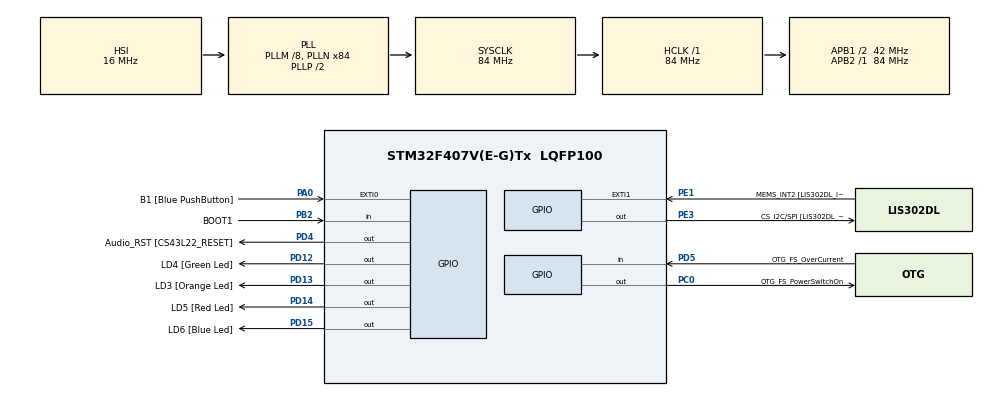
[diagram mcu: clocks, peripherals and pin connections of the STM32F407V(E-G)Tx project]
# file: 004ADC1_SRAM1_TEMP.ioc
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PA11.GPIO_Speed=GPIO_SPEED_FREQ_LOW
PD12.GPIO_Label=LD4 [Green Led]
PH0-OSC_IN.Signal=RCC_OSC_IN
ADC1.Rank-14\#ChannelRegularConversion=15
PC10.GPIO_PuPd=GPIO_NOPULL
PB10.GPIO_PuPd=GPIO_NOPULL
VP_ADC1_TempSens_Input.Mode=IN-TempSens
PA10.GPIO_PuPd=GPIO_NOPULL
ADC1.SamplingTime-6\#ChannelRegularConversion=ADC_SAMPLETIME_3CYCLES
PC12.Signal=I2S3_SD
PA14.GPIO_Label=SWCLK
PA6.GPIO_Label=SPI1_MISO [LIS302DL_SDO]
PB6.GPIO_Label=Audio_SCL [CS43L22_SCL]
ADC1.SamplingTime-12\#ChannelRegularConversion=ADC_SAMPLETIME_3CYCLES
PC15-OSC32_OUT.GPIO_Label=PC15-OSC32_OUT
ADC1.Channel-8\#ChannelRegularConversion=ADC_CHANNEL_TEMPSENSOR
PC3.GPIO_Speed=GPIO_SPEED_FREQ_LOW
RCC.SYSCLKSource=RCC_SYSCLKSOURCE_PLLCLK
PA6.GPIO_Mode=GPIO_MODE_AF_PP
PD14.GPIO_Speed=GPIO_SPEED_FREQ_LOW
ADC1.Channel-5\#ChannelRegularConversion=ADC_CHANNEL_TEMPSENSOR
ADC1.Rank-11\#ChannelRegularConversion=12
PD4.Signal=GPIO_Output
RCC.APB2TimFreq_Value=84000000
Dma.ADC1.0.Direction=DMA_PERIPH_TO_MEMORY
PB6.Signal=I2C1_SCL
ADC1.Channel-2\#ChannelRegularConversion=ADC_CHANNEL_TEMPSENSOR
PC7.Signal=I2S3_MCK
PC3.Signal=I2S2_SD
PE1.Signal=GPXTI1
Dma.ADC1.0.MemDataAlignment=DMA_MDATAALIGN_HALFWORD
PB2.Signal=GPIO_Input
PA5.GPIO_PuPd=GPIO_NOPULL
Dma.ADC1.0.PeriphInc=DMA_PINC_DISABLE
PD5.GPIO_Mode=GPIO_MODE_INPUT
PD14.GPIO_PuPd=GPIO_NOPULL
ADC1.Channel-15\#ChannelRegularConversion=ADC_CHANNEL_TEMPSENSOR
PB2.GPIO_PuPd=GPIO_NOPULL
ADC1.SamplingTime-0\#ChannelRegularConversion=ADC_SAMPLETIME_3CYCLES
PB9.Signal=I2C1_SDA
Mcu.Package=LQFP100
PD12.Signal=GPIO_Output
PA10.Signal=USB_OTG_FS_ID
PB9.GPIO_PuPd=GPIO_NOPULL
ADC1.SamplingTime-15\#ChannelRegularConversion=ADC_SAMPLETIME_3CYCLES
RCC.APB1TimFreq_Value=84000000
Dma.ADC1.0.FIFOMode=DMA_FIFOMODE_DISABLE
PC12.GPIO_PuPd=GPIO_NOPULL
PA6.GPIO_Speed=GPIO_SPEED_FREQ_LOW
PA12.GPIO_PuPd=GPIO_NOPULL
PA4.GPIO_Label=I2S3_WS [CS43L22_LRCK]
PD15.Signal=GPIO_Output
PC0.PinState=GPIO_PIN_SET
ADC1.Rank-4\#ChannelRegularConversion=5
ADC1.Channel-10\#ChannelRegularConversion=ADC_CHANNEL_TEMPSENSOR
Dma.ADC1.0.Instance=DMA2_Stream0
ADC1.Rank-0\#ChannelRegularConversion=1
PA9.GPIO_Label=VBUS_FS
PB6.GPIO_PuPd=GPIO_NOPULL
PA11.GPIO_Label=OTG_FS_DM
PE1.GPIO_PuPd=GPIO_NOPULL
PC0.Signal=GPIO_Output
RCC.APB1CLKDivider=RCC_HCLK_DIV2
PC14-OSC32_IN.Signal=RCC_OSC32_IN
PA0-WKUP.GPIO_Label=B1 [Blue PushButton]
PA0-WKUP.Signal=GPXTI0
ADC1.Channel-7\#ChannelRegularConversion=ADC_CHANNEL_TEMPSENSOR
PC10.GPIO_Mode=GPIO_MODE_AF_PP
PB10.GPIO_Mode=GPIO_MODE_AF_PP
Dma.ADC1.0.Priority=DMA_PRIORITY_LOW
PA9.Signal=USB_OTG_FS_VBUS
PC7.GPIO_PuPd=GPIO_NOPULL
PB10.Signal=I2S2_CK
PA5.Signal=SPI1_SCK
ADC1.Rank-12\#ChannelRegularConversion=13
PE1.GPIO_Label=MEMS_INT2 [LIS302DL_INT2]
PA7.GPIO_Speed=GPIO_SPEED_FREQ_LOW
ADC1.SamplingTime-14\#ChannelRegularConversion=ADC_SAMPLETIME_3CYCLES
PB2.GPIO_Mode=GPIO_MODE_INPUT
PD4.GPIO_Speed=GPIO_SPEED_FREQ_LOW
PE3.GPIO_PuPd=GPIO_NOPULL
PH1-OSC_OUT.GPIO_Label=PH1-OSC_OUT
ADC1.DMAContinuousRequests=ENABLE
ADC1.SamplingTime-10\#ChannelRegularConversion=ADC_SAMPLETIME_3CYCLES
ADC1.Rank-9\#ChannelRegularConversion=10
PC7.GPIO_Label=I2S3_MCK [CS43L22_MCLK]
ADC1.SamplingTime-1\#ChannelRegularConversion=ADC_SAMPLETIME_3CYCLES
PA4.Signal=I2S3_WS
PC12.GPIO_Mode=GPIO_MODE_AF_PP
ADC1.master=1
PA5.GPIO_Label=SPI1_SCK [LIS302DL_SCL/SPC]
PE3.GPIO_Speed=GPIO_SPEED_FREQ_LOW
PC12.GPIO_Label=I2S3_SD [CS43L22_SDIN]
ADC1.Rank-1\#ChannelRegularConversion=2
PA11.Signal=USB_OTG_FS_DM
ProjectManager.HeapSize=0x200
ADC1.SamplingTime-5\#ChannelRegularConversion=ADC_SAMPLETIME_3CYCLES
NVIC.PriorityGroup=NVIC_PRIORITYGROUP_0
PE3.Signal=GPIO_Output
PC3.GPIO_Label=PDM_OUT [MP45DT02_DOUT]
ADC1.SamplingTime-9\#ChannelRegularConversion=ADC_SAMPLETIME_3CYCLES
PB6.GPIO_Speed=GPIO_SPEED_FREQ_LOW
ADC1.Rank-5\#ChannelRegularConversion=6
Mcu.Family=STM32F4
PC3.GPIO_Mode=GPIO_MODE_AF_PP
RCC.CortexFreq_Value=84000000
PB10.GPIO_Speed=GPIO_SPEED_FREQ_LOW
PB6.GPIO_Mode=GPIO_MODE_AF_OD
ADC1.ContinuousConvMode=ENABLE
PD15.GPIO_Speed=GPIO_SPEED_FREQ_LOW
PC10.Signal=I2S3_CK
PA7.GPIO_Mode=GPIO_MODE_AF_PP
PC0.GPIO_Label=OTG_FS_PowerSwitchOn
PC10.GPIO_Speed=GPIO_SPEED_FREQ_LOW
PA11.GPIO_PuPd=GPIO_NOPULL
ADC1.Channel-14\#ChannelRegularConversion=ADC_CHANNEL_TEMPSENSOR
ProjectManager.StackSize=0x400
PD13.Signal=GPIO_Output
PA12.Signal=USB_OTG_FS_DP
ADC1.Channel-3\#ChannelRegularConversion=ADC_CHANNEL_TEMPSENSOR
RCC.HCLKFreq_Value=84000000
NVIC.DMA2_Stream0_IRQn=true\:0\:0\:false\:false\:true\:false\:true
RCC.AHBFreq_Value=84000000
PH0-OSC_IN.GPIO_Label=PH0-OSC_IN
PA9.GPIO_Mode=GPIO_MODE_INPUT
ADC1.Channel-0\#ChannelRegularConversion=ADC_CHANNEL_TEMPSENSOR
RCC.HSE_VALUE=8000000
PA4.GPIO_PuPd=GPIO_NOPULL
PA4.GPIO_Speed=GPIO_SPEED_FREQ_LOW
ADC1.SamplingTime-4\#ChannelRegularConversion=ADC_SAMPLETIME_3CYCLES
ADC1.Channel-6\#ChannelRegularConversion=ADC_CHANNEL_TEMPSENSOR
PA6.GPIO_PuPd=GPIO_NOPULL
ADC1.Rank-2\#ChannelRegularConversion=3
PA10.GPIO_Label=OTG_FS_ID
PC7.GPIO_Mode=GPIO_MODE_AF_PP
ADC1.Rank-15\#ChannelRegularConversion=16
PD13.GPIO_Label=LD3 [Orange Led]
ADC1.SamplingTime-11\#ChannelRegularConversion=ADC_SAMPLETIME_3CYCLES
PA6.Signal=SPI1_MISO
PD5.GPIO_Label=OTG_FS_OverCurrent
ADC1.SamplingTime-13\#ChannelRegularConversion=ADC_SAMPLETIME_3CYCLES
PD15.GPIO_PuPd=GPIO_NOPULL
ADC1.Channel-11\#ChannelRegularConversion=ADC_CHANNEL_TEMPSENSOR
PA10.GPIO_Speed=GPIO_SPEED_FREQ_LOW
PB9.GPIO_Speed=GPIO_SPEED_FREQ_LOW
PC14-OSC32_IN.GPIO_Label=PC14-OSC32_IN
PC0.GPIO_PuPd=GPIO_NOPULL
ADC1.Rank-6\#ChannelRegularConversion=7
Dma.Request0=ADC1
ADC1.SamplingTime-8\#ChannelRegularConversion=ADC_SAMPLETIME_3CYCLES
PA12.GPIO_Speed=GPIO_SPEED_FREQ_LOW
PB3.GPIO_Label=SWO
PD12.GPIO_Speed=GPIO_SPEED_FREQ_LOW
PD15.GPIO_Label=LD6 [Blue Led]
PB9.GPIO_Label=Audio_SDA [CS43L22_SDA]
ADC1.Channel-4\#ChannelRegularConversion=ADC_CHANNEL_TEMPSENSOR
PC10.GPIO_Label=I2S3_SCK [CS43L22_SCLK]
ADC1.Rank-10\#ChannelRegularConversion=11
ADC1.Rank-8\#ChannelRegularConversion=9
PD5.Signal=GPIO_Input
ADC1.Channel-13\#ChannelRegularConversion=ADC_CHANNEL_TEMPSENSOR
PE1.GPIO_ModeDefaultEXTI=GPIO_MODE_EVT_RISING
PA9.GPIO_PuPd=GPIO_NOPULL
PA12.GPIO_Label=OTG_FS_DP
ADC1.SamplingTime-2\#ChannelRegularConversion=ADC_SAMPLETIME_3CYCLES
PA10.GPIO_Mode=GPIO_MODE_AF_PP
PA13.Signal=SYS_JTMS-SWDIO
ADC1.Rank-13\#ChannelRegularConversion=14
PD4.GPIO_PuPd=GPIO_NOPULL
Dma.ADC1.0.PeriphDataAlignment=DMA_PDATAALIGN_HALFWORD
PC0.GPIO_Speed=GPIO_SPEED_FREQ_LOW
ProjectManager.TargetToolchain=STM32CubeIDE
PB10.GPIO_Label=CLK_IN [MP45DT02_CLK]
Dma.ADC1.0.Mode=DMA_NORMAL
ADC1.Channel-1\#ChannelRegularConversion=ADC_CHANNEL_TEMPSENSOR
RCC.LSE_VALUE=32768
PC15-OSC32_OUT.Signal=RCC_OSC32_OUT
PA7.GPIO_PuPd=GPIO_NOPULL
board=STM32F407G-DISC1
PD13.GPIO_Speed=GPIO_SPEED_FREQ_LOW
PC7.GPIO_Speed=GPIO_SPEED_FREQ_LOW
RCC.VCOOutputFreq_Value=168000000
PB9.GPIO_Mode=GPIO_MODE_AF_OD
PA12.GPIO_Mode=GPIO_MODE_AF_PP
PA4.GPIO_Mode=GPIO_MODE_AF_PP
ADC1.Channel-12\#ChannelRegularConversion=ADC_CHANNEL_TEMPSENSOR
RCC.APB2Freq_Value=84000000
PD4.GPIO_Label=Audio_RST [CS43L22_RESET]
PH1-OSC_OUT.Signal=RCC_OSC_OUT
PD13.GPIO_PuPd=GPIO_NOPULL
PD5.GPIO_PuPd=GPIO_NOPULL
PD14.GPIO_Label=LD5 [Red Led]
ADC1.NbrOfConversion=16
Mcu.Name=STM32F407V(E-G)Tx
PA13.GPIO_Label=SWDIO
ADC1.Channel-9\#ChannelRegularConversion=ADC_CHANNEL_TEMPSENSOR
PD14.Signal=GPIO_Output
RCC.48MHZClocksFreq_Value=24000000
PB3.Signal=SYS_JTDO-SWO
NVIC.EXTI0_IRQn=true\:0\:0\:false\:false\:true\:true\:true
RCC.SYSCLKFreq_VALUE=84000000
PA7.GPIO_Label=SPI1_MOSI [LIS302DL_SDA/SDI/SDO]
ADC1.Rank-3\#ChannelRegularConversion=4
ADC1.SamplingTime-3\#ChannelRegularConversion=ADC_SAMPLETIME_3CYCLES
PA14.Signal=SYS_JTCK-SWCLK
Dma.ADC1.0.MemInc=DMA_MINC_ENABLE
PB2.GPIO_Label=BOOT1
RCC.HSI_VALUE=16000000
ADC1.Rank-7\#ChannelRegularConversion=8
PA5.GPIO_Speed=GPIO_SPEED_FREQ_LOW
RCC.PLLQ=7
ADC1.NbrOfConversionFlag=1
RCC.PLLM=8
RCC.PLLN=84
PE3.GPIO_Label=CS_I2C/SPI [LIS302DL_CS_I2C/SPI]
ADC1.SamplingTime-7\#ChannelRegularConversion=ADC_SAMPLETIME_3CYCLES
PA11.GPIO_Mode=GPIO_MODE_AF_PP
RCC.APB1Freq_Value=42000000
PA5.GPIO_Mode=GPIO_MODE_AF_PP
PC12.GPIO_Speed=GPIO_SPEED_FREQ_LOW
PC3.GPIO_PuPd=GPIO_NOPULL
PD12.GPIO_PuPd=GPIO_NOPULL
PA7.Signal=SPI1_MOSI

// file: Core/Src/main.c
/* USER CODE BEGIN Header */
/**
  ******************************************************************************
  * @file           : main.c
  * @brief          : Main program body
  ******************************************************************************
  * @attention
  *
  * <h2><center>&copy; Copyright (c) 2021 STMicroelectronics.
  * All rights reserved.</center></h2>
  *
  * This software component is licensed by ST under BSD 3-Clause license,
  * the "License"; You may not use this file except in compliance with the
  * License. You may obtain a copy of the License at:
  *                        opensource.org/licenses/BSD-3-Clause
  *
  ******************************************************************************
  */
/* USER CODE END Header */
#include "main.h"

/* USER CODE BEGIN Includes */
#include <stdint.h>
/* USER CODE END Includes */

ADC_HandleTypeDef hadc1;
DMA_HandleTypeDef hdma_adc1;

/* USER CODE BEGIN PV */

uint16_t temp_data[16];

/* USER CODE END PV */

void SystemClock_Config(void);
static void MX_GPIO_Init(void);
static void MX_DMA_Init(void);
static void MX_ADC1_Init(void);

int main(void)
{

  /* MCU Configuration--------------------------------------------------------*/

  /* Reset of all peripherals, Initializes the Flash interface and the Systick. */
  HAL_Init();

  /* Configure the system clock */
  SystemClock_Config();

  /* Initialize all configured peripherals */
  MX_GPIO_Init();
  MX_DMA_Init();
  MX_ADC1_Init();

  /* Infinite loop */
  while (1)
  {

  }
}

void SystemClock_Config(void)
{
  RCC_OscInitTypeDef RCC_OscInitStruct = {0};
  RCC_ClkInitTypeDef RCC_ClkInitStruct = {0};

  /** Configure the main internal regulator output voltage
  */
  __HAL_RCC_PWR_CLK_ENABLE();
  __HAL_PWR_VOLTAGESCALING_CONFIG(PWR_REGULATOR_VOLTAGE_SCALE1);
  /** Initializes the RCC Oscillators according to the specified parameters
  * in the RCC_OscInitTypeDef structure.
  */
  RCC_OscInitStruct.OscillatorType = RCC_OSCILLATORTYPE_HSI;
  RCC_OscInitStruct.HSIState = RCC_HSI_ON;
  RCC_OscInitStruct.HSICalibrationValue = RCC_HSICALIBRATION_DEFAULT;
  RCC_OscInitStruct.PLL.PLLState = RCC_PLL_ON;
  RCC_OscInitStruct.PLL.PLLSource = RCC_PLLSOURCE_HSI;
  RCC_OscInitStruct.PLL.PLLM = 8;
  RCC_OscInitStruct.PLL.PLLN = 84;
  RCC_OscInitStruct.PLL.PLLP = RCC_PLLP_DIV2;
  RCC_OscInitStruct.PLL.PLLQ = 7;
  if (HAL_RCC_OscConfig(&RCC_OscInitStruct) != HAL_OK)
  {
    Error_Handler();
  }
  /** Initializes the CPU, AHB and APB buses clocks
  */
  RCC_ClkInitStruct.ClockType = RCC_CLOCKTYPE_HCLK|RCC_CLOCKTYPE_SYSCLK
                              |RCC_CLOCKTYPE_PCLK1|RCC_CLOCKTYPE_PCLK2;
  RCC_ClkInitStruct.SYSCLKSource = RCC_SYSCLKSOURCE_PLLCLK;
  RCC_ClkInitStruct.AHBCLKDivider = RCC_SYSCLK_DIV1;
  RCC_ClkInitStruct.APB1CLKDivider = RCC_HCLK_DIV2;
  RCC_ClkInitStruct.APB2CLKDivider = RCC_HCLK_DIV1;

  if (HAL_RCC_ClockConfig(&RCC_ClkInitStruct, FLASH_LATENCY_2) != HAL_OK)
  {
    Error_Handler();
  }
}

static void MX_ADC1_Init(void)
{

  ADC_ChannelConfTypeDef sConfig = {0};

  /** Configure the global features of the ADC (Clock, Resolution, Data Alignment and number of conversion)
  */
  hadc1.Instance = ADC1;
  hadc1.Init.ClockPrescaler = ADC_CLOCK_SYNC_PCLK_DIV4;
  hadc1.Init.Resolution = ADC_RESOLUTION_12B;
  hadc1.Init.ScanConvMode = DISABLE;
  hadc1.Init.ContinuousConvMode = ENABLE;
  hadc1.Init.DiscontinuousConvMode = DISABLE;
  hadc1.Init.ExternalTrigConvEdge = ADC_EXTERNALTRIGCONVEDGE_NONE;
  hadc1.Init.ExternalTrigConv = ADC_SOFTWARE_START;
  hadc1.Init.DataAlign = ADC_DATAALIGN_RIGHT;
  hadc1.Init.NbrOfConversion = 16;
  hadc1.Init.DMAContinuousRequests = ENABLE;
  hadc1.Init.EOCSelection = ADC_EOC_SINGLE_CONV;
  if (HAL_ADC_Init(&hadc1) != HAL_OK)
  {
    Error_Handler();
  }
  /** Configure for the selected ADC regular channel its corresponding rank in the sequencer and its sample time.
  */
  sConfig.Channel = ADC_CHANNEL_TEMPSENSOR;
  sConfig.Rank = 1;
  sConfig.SamplingTime = ADC_SAMPLETIME_3CYCLES;
  if (HAL_ADC_ConfigChannel(&hadc1, &sConfig) != HAL_OK)
  {
    Error_Handler();
  }
  /** Configure for the selected ADC regular channel its corresponding rank in the sequencer and its sample time.
  */
  sConfig.Rank = 2;
  if (HAL_ADC_ConfigChannel(&hadc1, &sConfig) != HAL_OK)
  {
    Error_Handler();
  }
  /** Configure for the selected ADC regular channel its corresponding rank in the sequencer and its sample time.
  */
  sConfig.Rank = 3;
  if (HAL_ADC_ConfigChannel(&hadc1, &sConfig) != HAL_OK)
  {
    Error_Handler();
  }
  /** Configure for the selected ADC regular channel its corresponding rank in the sequencer and its sample time.
  */
  sConfig.Rank = 4;
  if (HAL_ADC_ConfigChannel(&hadc1, &sConfig) != HAL_OK)
  {
    Error_Handler();
  }
  /** Configure for the selected ADC regular channel its corresponding rank in the sequencer and its sample time.
  */
  sConfig.Rank = 5;
  if (HAL_ADC_ConfigChannel(&hadc1, &sConfig) != HAL_OK)
  {
    Error_Handler();
  }
  /** Configure for the selected ADC regular channel its corresponding rank in the sequencer and its sample time.
  */
  sConfig.Rank = 6;
  if (HAL_ADC_ConfigChannel(&hadc1, &sConfig) != HAL_OK)
  {
    Error_Handler();
  }
  /** Configure for the selected ADC regular channel its corresponding rank in the sequencer and its sample time.
  */
  sConfig.Rank = 7;
  if (HAL_ADC_ConfigChannel(&hadc1, &sConfig) != HAL_OK)
  {
    Error_Handler();
  }
  /** Configure for the selected ADC regular channel its corresponding rank in the sequencer and its sample time.
  */
  sConfig.Rank = 8;
  if (HAL_ADC_ConfigChannel(&hadc1, &sConfig) != HAL_OK)
  {
    Error_Handler();
  }
  /** Configure for the selected ADC regular channel its corresponding rank in the sequencer and its sample time.
  */
  sConfig.Rank = 9;
  if (HAL_ADC_ConfigChannel(&hadc1, &sConfig) != HAL_OK)
  {
    Error_Handler();
  }
  /** Configure for the selected ADC regular channel its corresponding rank in the sequencer and its sample time.
  */
  sConfig.Rank = 10;
  if (HAL_ADC_ConfigChannel(&hadc1, &sConfig) != HAL_OK)
  {
    Error_Handler();
  }
  /** Configure for the selected ADC regular channel its corresponding rank in the sequencer and its sample time.
  */
  sConfig.Rank = 11;
  if (HAL_ADC_ConfigChannel(&hadc1, &sConfig) != HAL_OK)
  {
    Error_Handler();
  }
  /** Configure for the selected ADC regular channel its corresponding rank in the sequencer and its sample time.
  */
  sConfig.Rank = 12;
  if (HAL_ADC_ConfigChannel(&hadc1, &sConfig) != HAL_OK)
  {
    Error_Handler();
  }
  /** Configure for the selected ADC regular channel its corresponding rank in the sequencer and its sample time.
  */
  sConfig.Rank = 13;
  if (HAL_ADC_ConfigChannel(&hadc1, &sConfig) != HAL_OK)
  {
    Error_Handler();
  }
  /** Configure for the selected ADC regular channel its corresponding rank in the sequencer and its sample time.
  */
  sConfig.Rank = 14;
  if (HAL_ADC_ConfigChannel(&hadc1, &sConfig) != HAL_OK)
  {
    Error_Handler();
  }
  /** Configure for the selected ADC regular channel its corresponding rank in the sequencer and its sample time.
  */
  sConfig.Rank = 15;
  if (HAL_ADC_ConfigChannel(&hadc1, &sConfig) != HAL_OK)
  {
    Error_Handler();
  }
  /** Configure for the selected ADC regular channel its corresponding rank in the sequencer and its sample time.
  */
  sConfig.Rank = 16;
  if (HAL_ADC_ConfigChannel(&hadc1, &sConfig) != HAL_OK)
  {
    Error_Handler();
  }

}

static void MX_DMA_Init(void)
{

  /* DMA controller clock enable */
  __HAL_RCC_DMA2_CLK_ENABLE();

  /* DMA interrupt init */
  /* DMA2_Stream0_IRQn interrupt configuration */
  HAL_NVIC_SetPriority(DMA2_Stream0_IRQn, 0, 0);
  HAL_NVIC_EnableIRQ(DMA2_Stream0_IRQn);

}

static void MX_GPIO_Init(void)
{
  GPIO_InitTypeDef GPIO_InitStruct = {0};

  /* GPIO Ports Clock Enable */
  __HAL_RCC_GPIOE_CLK_ENABLE();
  __HAL_RCC_GPIOC_CLK_ENABLE();
  __HAL_RCC_GPIOH_CLK_ENABLE();
  __HAL_RCC_GPIOA_CLK_ENABLE();
  __HAL_RCC_GPIOB_CLK_ENABLE();
  __HAL_RCC_GPIOD_CLK_ENABLE();

  /*Configure GPIO pin Output Level */
  HAL_GPIO_WritePin(CS_I2C_SPI_GPIO_Port, CS_I2C_SPI_Pin, GPIO_PIN_RESET);

  /*Configure GPIO pin Output Level */
  HAL_GPIO_WritePin(OTG_FS_PowerSwitchOn_GPIO_Port, OTG_FS_PowerSwitchOn_Pin, GPIO_PIN_SET);

  /*Configure GPIO pin Output Level */
  HAL_GPIO_WritePin(GPIOD, LD4_Pin|LD3_Pin|LD5_Pin|LD6_Pin
                          |Audio_RST_Pin, GPIO_PIN_RESET);

  /*Configure GPIO pin : CS_I2C_SPI_Pin */
  GPIO_InitStruct.Pin = CS_I2C_SPI_Pin;
  GPIO_InitStruct.Mode = GPIO_MODE_OUTPUT_PP;
  GPIO_InitStruct.Pull = GPIO_NOPULL;
  GPIO_InitStruct.Speed = GPIO_SPEED_FREQ_LOW;
  HAL_GPIO_Init(CS_I2C_SPI_GPIO_Port, &GPIO_InitStruct);

  /*Configure GPIO pin : OTG_FS_PowerSwitchOn_Pin */
  GPIO_InitStruct.Pin = OTG_FS_PowerSwitchOn_Pin;
  GPIO_InitStruct.Mode = GPIO_MODE_OUTPUT_PP;
  GPIO_InitStruct.Pull = GPIO_NOPULL;
  GPIO_InitStruct.Speed = GPIO_SPEED_FREQ_LOW;
  HAL_GPIO_Init(OTG_FS_PowerSwitchOn_GPIO_Port, &GPIO_InitStruct);

  /*Configure GPIO pin : PDM_OUT_Pin */
  GPIO_InitStruct.Pin = PDM_OUT_Pin;
  GPIO_InitStruct.Mode = GPIO_MODE_AF_PP;
  GPIO_InitStruct.Pull = GPIO_NOPULL;
  GPIO_InitStruct.Speed = GPIO_SPEED_FREQ_LOW;
  GPIO_InitStruct.Alternate = GPIO_AF5_SPI2;
  HAL_GPIO_Init(PDM_OUT_GPIO_Port, &GPIO_InitStruct);

  /*Configure GPIO pin : B1_Pin */
  GPIO_InitStruct.Pin = B1_Pin;
  GPIO_InitStruct.Mode = GPIO_MODE_IT_RISING;
  GPIO_InitStruct.Pull = GPIO_NOPULL;
  HAL_GPIO_Init(B1_GPIO_Port, &GPIO_InitStruct);

  /*Configure GPIO pin : I2S3_WS_Pin */
  GPIO_InitStruct.Pin = I2S3_WS_Pin;
  GPIO_InitStruct.Mode = GPIO_MODE_AF_PP;
  GPIO_InitStruct.Pull = GPIO_NOPULL;
  GPIO_InitStruct.Speed = GPIO_SPEED_FREQ_LOW;
  GPIO_InitStruct.Alternate = GPIO_AF6_SPI3;
  HAL_GPIO_Init(I2S3_WS_GPIO_Port, &GPIO_InitStruct);

  /*Configure GPIO pins : SPI1_SCK_Pin SPI1_MISO_Pin SPI1_MOSI_Pin */
  GPIO_InitStruct.Pin = SPI1_SCK_Pin|SPI1_MISO_Pin|SPI1_MOSI_Pin;
  GPIO_InitStruct.Mode = GPIO_MODE_AF_PP;
  GPIO_InitStruct.Pull = GPIO_NOPULL;
  GPIO_InitStruct.Speed = GPIO_SPEED_FREQ_LOW;
  GPIO_InitStruct.Alternate = GPIO_AF5_SPI1;
  HAL_GPIO_Init(GPIOA, &GPIO_InitStruct);

  /*Configure GPIO pin : BOOT1_Pin */
  GPIO_InitStruct.Pin = BOOT1_Pin;
  GPIO_InitStruct.Mode = GPIO_MODE_INPUT;
  GPIO_InitStruct.Pull = GPIO_NOPULL;
  HAL_GPIO_Init(BOOT1_GPIO_Port, &GPIO_InitStruct);

  /*Configure GPIO pin : CLK_IN_Pin */
  GPIO_InitStruct.Pin = CLK_IN_Pin;
  GPIO_InitStruct.Mode = GPIO_MODE_AF_PP;
  GPIO_InitStruct.Pull = GPIO_NOPULL;
  GPIO_InitStruct.Speed = GPIO_SPEED_FREQ_LOW;
  GPIO_InitStruct.Alternate = GPIO_AF5_SPI2;
  HAL_GPIO_Init(CLK_IN_GPIO_Port, &GPIO_InitStruct);

  /*Configure GPIO pins : LD4_Pin LD3_Pin LD5_Pin LD6_Pin
                           Audio_RST_Pin */
  GPIO_InitStruct.Pin = LD4_Pin|LD3_Pin|LD5_Pin|LD6_Pin
                          |Audio_RST_Pin;
  GPIO_InitStruct.Mode = GPIO_MODE_OUTPUT_PP;
  GPIO_InitStruct.Pull = GPIO_NOPULL;
  GPIO_InitStruct.Speed = GPIO_SPEED_FREQ_LOW;
  HAL_GPIO_Init(GPIOD, &GPIO_InitStruct);

  /*Configure GPIO pins : I2S3_MCK_Pin I2S3_SCK_Pin I2S3_SD_Pin */
  GPIO_InitStruct.Pin = I2S3_MCK_Pin|I2S3_SCK_Pin|I2S3_SD_Pin;
  GPIO_InitStruct.Mode = GPIO_MODE_AF_PP;
  GPIO_InitStruct.Pull = GPIO_NOPULL;
  GPIO_InitStruct.Speed = GPIO_SPEED_FREQ_LOW;
  GPIO_InitStruct.Alternate = GPIO_AF6_SPI3;
  HAL_GPIO_Init(GPIOC, &GPIO_InitStruct);

  /*Configure GPIO pin : VBUS_FS_Pin */
  GPIO_InitStruct.Pin = VBUS_FS_Pin;
  GPIO_InitStruct.Mode = GPIO_MODE_INPUT;
  GPIO_InitStruct.Pull = GPIO_NOPULL;
  HAL_GPIO_Init(VBUS_FS_GPIO_Port, &GPIO_InitStruct);

  /*Configure GPIO pins : OTG_FS_ID_Pin OTG_FS_DM_Pin OTG_FS_DP_Pin */
  GPIO_InitStruct.Pin = OTG_FS_ID_Pin|OTG_FS_DM_Pin|OTG_FS_DP_Pin;
  GPIO_InitStruct.Mode = GPIO_MODE_AF_PP;
  GPIO_InitStruct.Pull = GPIO_NOPULL;
  GPIO_InitStruct.Speed = GPIO_SPEED_FREQ_LOW;
  GPIO_InitStruct.Alternate = GPIO_AF10_OTG_FS;
  HAL_GPIO_Init(GPIOA, &GPIO_InitStruct);

  /*Configure GPIO pin : OTG_FS_OverCurrent_Pin */
  GPIO_InitStruct.Pin = OTG_FS_OverCurrent_Pin;
  GPIO_InitStruct.Mode = GPIO_MODE_INPUT;
  GPIO_InitStruct.Pull = GPIO_NOPULL;
  HAL_GPIO_Init(OTG_FS_OverCurrent_GPIO_Port, &GPIO_InitStruct);

  /*Configure GPIO pins : Audio_SCL_Pin Audio_SDA_Pin */
  GPIO_InitStruct.Pin = Audio_SCL_Pin|Audio_SDA_Pin;
  GPIO_InitStruct.Mode = GPIO_MODE_AF_OD;
  GPIO_InitStruct.Pull = GPIO_PULLUP;
  GPIO_InitStruct.Speed = GPIO_SPEED_FREQ_LOW;
  GPIO_InitStruct.Alternate = GPIO_AF4_I2C1;
  HAL_GPIO_Init(GPIOB, &GPIO_InitStruct);

  /*Configure GPIO pin : MEMS_INT2_Pin */
  GPIO_InitStruct.Pin = MEMS_INT2_Pin;
  GPIO_InitStruct.Mode = GPIO_MODE_EVT_RISING;
  GPIO_InitStruct.Pull = GPIO_NOPULL;
  HAL_GPIO_Init(MEMS_INT2_GPIO_Port, &GPIO_InitStruct);

  /* EXTI interrupt init*/
  HAL_NVIC_SetPriority(EXTI0_IRQn, 0, 0);
  HAL_NVIC_EnableIRQ(EXTI0_IRQn);

}

/* USER CODE BEGIN 4 */

void HAL_GPIO_EXTI_Callback(uint16_t GPIO_Pin){
	static uint8_t button_pressed = RESET;

	if(button_pressed == RESET){
		HAL_ADC_Start_DMA(&hadc1, (uint32_t *)temp_data, 16);
		button_pressed = SET;
	}
}

void HAL_ADC_ConvCpltCallback(ADC_HandleTypeDef* hadc){

}

/* USER CODE END 4 */

void Error_Handler(void)
{
  __disable_irq();
  while (1)
  {
  }
}

/************************ (C) COPYRIGHT STMicroelectronics *****END OF FILE****/
